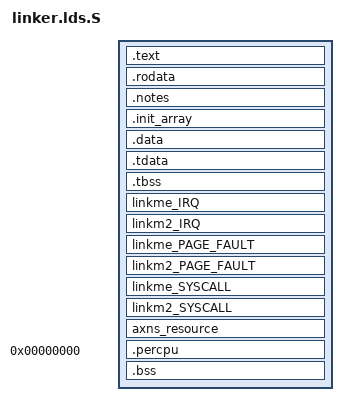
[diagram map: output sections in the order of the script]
OUTPUT_ARCH(%ARCH%)

BASE_ADDRESS = %KERNEL_BASE%;

ENTRY(_start)
SECTIONS
{
    . = BASE_ADDRESS;
    _skernel = .;

    .text : ALIGN(4K) {
        _stext = .;
        *(.text.boot)
        *(.text .text.*)
        . = ALIGN(4K);
        _etext = .;
    }

    _srodata = .;
    .rodata : ALIGN(4K) {
        *(.rodata .rodata.*)
        *(.srodata .srodata.*)
        *(.sdata2 .sdata2.*)
    }

    .notes : ALIGN(0x10) {
        __start_notes = .;
        *(.note.*)
        __stop_notes = .;
    }

    .init_array : ALIGN(4K) {
        __init_array_start = .;
        KEEP(*(.init_array .init_array.*))
        __init_array_end = .;
    }

    . = ALIGN(4K);
    _erodata = .;

    .data : ALIGN(4K) {
        _sdata = .;
        *(.data.boot_page_table)
        . = ALIGN(4K);
        *(.data .data.*)
        *(.sdata .sdata.*)
        *(.got .got.*)
    }

    .tdata : ALIGN(0x10) {
        _stdata = .;
        *(.tdata .tdata.*)
        _etdata = .;
    }

    .tbss : ALIGN(0x10) {
        _stbss = .;
        *(.tbss .tbss.*)
        *(.tcommon)
        _etbss = .;
    }

    linkme_IRQ : { *(linkme_IRQ) }
    linkm2_IRQ : { *(linkm2_IRQ) }
    linkme_PAGE_FAULT : { *(linkme_PAGE_FAULT) }
    linkm2_PAGE_FAULT : { *(linkm2_PAGE_FAULT) }
    linkme_SYSCALL : { *(linkme_SYSCALL) }
    linkm2_SYSCALL : { *(linkm2_SYSCALL) }
    axns_resource : { *(axns_resource) }

    . = ALIGN(4K);
    _percpu_start = .;
    .percpu 0x0 : AT(_percpu_start) {
        _percpu_load_start = .;
        *(.percpu .percpu.*)
        _percpu_load_end = .;
        . = _percpu_load_start + ALIGN(64) * %CPU_NUM%;
        _percpu_end = _percpu_start + ALIGN(64) * %CPU_NUM%;
    }
    . = _percpu_end;

    . = ALIGN(4K);
    _edata = .;

    .bss : AT(_edata) ALIGN(4K) {
        boot_stack = .;
        *(.bss.stack)
        . = ALIGN(4K);
        boot_stack_top = .;

        _sbss = .;
        *(.bss .bss.*)
        *(.sbss .sbss.*)
        *(COMMON)
        . = ALIGN(4K);
        _ebss = .;
    }

    _ekernel = .;

	/DISCARD/ : {
        *(.comment) *(.gnu*) *(.note.GNU-stack) *(.note.gnu.property) *(.eh_frame*)
    }
}
